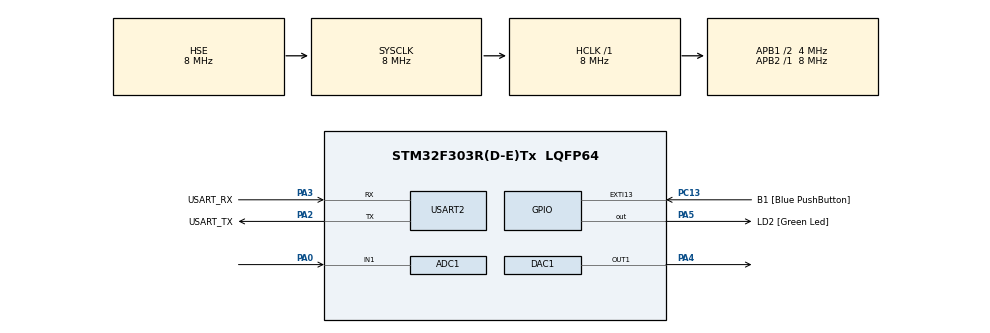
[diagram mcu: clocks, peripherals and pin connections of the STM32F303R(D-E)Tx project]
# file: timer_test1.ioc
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ADC1.Channel-0\#ChannelRegularConversion=ADC_CHANNEL_1
ADC1.NbrOfConversionFlag=1
ADC1.Offset-0\#ChannelRegularConversion=0
ADC1.OffsetNumber-0\#ChannelRegularConversion=ADC_OFFSET_NONE
ADC1.Rank-0\#ChannelRegularConversion=1
ADC1.SamplingTime-0\#ChannelRegularConversion=ADC_SAMPLETIME_1CYCLE_5
ADC1.master=1
Mcu.Family=STM32F3
Mcu.Name=STM32F303R(D-E)Tx
Mcu.Package=LQFP64
NVIC.PriorityGroup=NVIC_PRIORITYGROUP_0
NVIC.TIM3_IRQn=true\:0\:0\:false\:false\:true\:true\:true
PA0.Mode=IN1-Single-Ended
PA0.Signal=ADC1_IN1
PA13.GPIO_Label=TMS
PA13.Mode=Serial_Wire
PA13.Signal=SYS_JTMS-SWDIO
PA14.GPIO_Label=TCK
PA14.Mode=Serial_Wire
PA14.Signal=SYS_JTCK-SWCLK
PA2.GPIO_Label=USART_TX
PA2.GPIO_Mode=GPIO_MODE_AF_PP
PA2.GPIO_PuPd=GPIO_NOPULL
PA2.GPIO_Speed=GPIO_SPEED_FREQ_LOW
PA2.Mode=Asynchronous
PA2.Signal=USART2_TX
PA3.GPIO_Label=USART_RX
PA3.GPIO_Mode=GPIO_MODE_AF_PP
PA3.GPIO_PuPd=GPIO_NOPULL
PA3.GPIO_Speed=GPIO_SPEED_FREQ_LOW
PA3.Mode=Asynchronous
PA3.Signal=USART2_RX
PA4.Signal=COMP_DAC11_group
PA5.GPIO_Label=LD2 [Green Led]
PA5.GPIO_Mode=GPIO_MODE_OUTPUT_PP
PA5.GPIO_PuPd=GPIO_NOPULL
PA5.GPIO_Speed=GPIO_SPEED_FREQ_LOW
PA5.Signal=GPIO_Output
PB3.GPIO_Label=SWO
PB3.Signal=SYS_JTDO-TRACESWO
PC13.GPIO_Label=B1 [Blue PushButton]
PC13.GPIO_ModeDefaultEXTI=GPIO_MODE_IT_FALLING
PC13.Signal=GPXTI13
PC14-OSC32_IN.Signal=RCC_OSC32_IN
PC15-OSC32_OUT.Signal=RCC_OSC32_OUT
PF0-OSC_IN.Mode=HSE-External-Oscillator
PF0-OSC_IN.Signal=RCC_OSC_IN
PF1-OSC_OUT.Mode=HSE-External-Oscillator
PF1-OSC_OUT.Signal=RCC_OSC_OUT
ProjectManager.HeapSize=0x200
ProjectManager.StackSize=0x400
ProjectManager.TargetToolchain=MDK-ARM V5
RCC.AHBFreq_Value=8000000
RCC.APB1CLKDivider=RCC_HCLK_DIV2
RCC.APB1Freq_Value=4000000
RCC.APB1TimFreq_Value=8000000
RCC.APB2Freq_Value=8000000
RCC.APB2TimFreq_Value=8000000
RCC.CortexFreq_Value=8000000
RCC.HCLKFreq_Value=8000000
RCC.HSE_VALUE=8000000
RCC.HSI_VALUE=8000000
RCC.LSE_VALUE=32768
RCC.PLLM=8
RCC.PLLMUL=RCC_PLL_MUL9
RCC.PLLN=336
RCC.PLLP=RCC_PLLP_DIV4
RCC.PLLQ=7
RCC.PLLSourceVirtual=RCC_PLLSOURCE_HSE
RCC.RCC_PLLsource_Clock_Source_FROM_HSE=RCC_HSE_PREDIV_DIV2
RCC.SYSCLKFreq_VALUE=8000000
RCC.SYSCLKSourceVirtual=RCC_SYSCLKSOURCE_HSE
RCC.USBFreq_Value=72000000
SH.COMP_DAC11_group.0=DAC1_OUT1,DAC_OUT1
TIM3.Period=19
TIM3.Prescaler=79
USART2.VirtualMode-Asynchronous=VM_ASYNC
VP_TIM3_VS_ClockSourceINT.Mode=Internal
board=NUCLEO-F303RE

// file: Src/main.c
/* USER CODE BEGIN Header */
/**
  ******************************************************************************
  * @file           : main.c
  * @brief          : Main program body
  ******************************************************************************
  * @attention
  *
  * <h2><center>&copy; Copyright (c) 2019 STMicroelectronics.
  * All rights reserved.</center></h2>
  *
  * This software component is licensed by ST under BSD 3-Clause license,
  * the "License"; You may not use this file except in compliance with the
  * License. You may obtain a copy of the License at:
  *                        opensource.org/licenses/BSD-3-Clause
  *
  ******************************************************************************
  */
/* USER CODE END Header */

#include "main.h"

ADC_HandleTypeDef hadc1;

DAC_HandleTypeDef hdac1;

TIM_HandleTypeDef htim3;

UART_HandleTypeDef huart2;

uint32_t dacInput,up;
float dac_value_variable=2;
float dac_output_variable;

void SystemClock_Config(void);
static void MX_GPIO_Init(void);
static void MX_ADC1_Init(void);
static void MX_DAC1_Init(void);
static void MX_TIM3_Init(void);
static void MX_USART2_UART_Init(void);

/* USER CODE BEGIN 0 */
void HAL_TIM_PeriodElapsedCallback(TIM_HandleTypeDef*htim)
{

	if(htim->Instance==TIM3)
	{
		if(up==1)
		{
			dacInput=dacInput+256;
			if (dacInput==3840)
			{up=1;}
		}
		else
		{dacInput=dacInput-256;
			if (dacInput==0)
			{up =1;}
		}
	}

	HAL_DAC_Start(&hdac1, DAC_CHANNEL_1);
	HAL_DAC_SetValue(&hdac1,DAC_CHANNEL_1,DAC_ALIGN_8B_R,dac_value_variable);
	dac_output_variable=(3300*dac_value_variable)/4096;
}
/* USER CODE END 0 */

int main(void)
{

  /* MCU Configuration--------------------------------------------------------*/

  /* Reset of all peripherals, Initializes the Flash interface and the Systick. */
  HAL_Init();

  /* Configure the system clock */
  SystemClock_Config();

  /* Initialize all configured peripherals */
  MX_GPIO_Init();
  MX_ADC1_Init();
  MX_DAC1_Init();
  MX_TIM3_Init();
  MX_USART2_UART_Init();
  /* USER CODE BEGIN 2 */
	HAL_TIM_Base_Start_IT(&htim3);
  /* USER CODE END 2 */

  /* Infinite loop */
  while (1)
  {

  }
}

void SystemClock_Config(void)
{
  RCC_OscInitTypeDef RCC_OscInitStruct = {0};
  RCC_ClkInitTypeDef RCC_ClkInitStruct = {0};
  RCC_PeriphCLKInitTypeDef PeriphClkInit = {0};

  /** Initializes the CPU, AHB and APB busses clocks
  */
  RCC_OscInitStruct.OscillatorType = RCC_OSCILLATORTYPE_HSE;
  RCC_OscInitStruct.HSEState = RCC_HSE_ON;
  RCC_OscInitStruct.HSIState = RCC_HSI_ON;
  RCC_OscInitStruct.PLL.PLLState = RCC_PLL_ON;
  RCC_OscInitStruct.PLL.PLLSource = RCC_PLLSOURCE_HSE;
  RCC_OscInitStruct.PLL.PLLMUL = RCC_PLL_MUL9;
  RCC_OscInitStruct.PLL.PREDIV = RCC_PREDIV_DIV1;
  if (HAL_RCC_OscConfig(&RCC_OscInitStruct) != HAL_OK)
  {
    Error_Handler();
  }
  /** Initializes the CPU, AHB and APB busses clocks
  */
  RCC_ClkInitStruct.ClockType = RCC_CLOCKTYPE_HCLK|RCC_CLOCKTYPE_SYSCLK
                              |RCC_CLOCKTYPE_PCLK1|RCC_CLOCKTYPE_PCLK2;
  RCC_ClkInitStruct.SYSCLKSource = RCC_SYSCLKSOURCE_HSE;
  RCC_ClkInitStruct.AHBCLKDivider = RCC_SYSCLK_DIV1;
  RCC_ClkInitStruct.APB1CLKDivider = RCC_HCLK_DIV2;
  RCC_ClkInitStruct.APB2CLKDivider = RCC_HCLK_DIV1;

  if (HAL_RCC_ClockConfig(&RCC_ClkInitStruct, FLASH_LATENCY_0) != HAL_OK)
  {
    Error_Handler();
  }
  PeriphClkInit.PeriphClockSelection = RCC_PERIPHCLK_USART2|RCC_PERIPHCLK_ADC12
                              |RCC_PERIPHCLK_TIM34;
  PeriphClkInit.Usart2ClockSelection = RCC_USART2CLKSOURCE_PCLK1;
  PeriphClkInit.Adc12ClockSelection = RCC_ADC12PLLCLK_DIV1;
  PeriphClkInit.Tim34ClockSelection = RCC_TIM34CLK_HCLK;
  if (HAL_RCCEx_PeriphCLKConfig(&PeriphClkInit) != HAL_OK)
  {
    Error_Handler();
  }
}

static void MX_ADC1_Init(void)
{

  ADC_MultiModeTypeDef multimode = {0};
  ADC_ChannelConfTypeDef sConfig = {0};

  /** Common config
  */
  hadc1.Instance = ADC1;
  hadc1.Init.ClockPrescaler = ADC_CLOCK_ASYNC_DIV1;
  hadc1.Init.Resolution = ADC_RESOLUTION_12B;
  hadc1.Init.ScanConvMode = ADC_SCAN_DISABLE;
  hadc1.Init.ContinuousConvMode = DISABLE;
  hadc1.Init.DiscontinuousConvMode = DISABLE;
  hadc1.Init.ExternalTrigConvEdge = ADC_EXTERNALTRIGCONVEDGE_NONE;
  hadc1.Init.ExternalTrigConv = ADC_SOFTWARE_START;
  hadc1.Init.DataAlign = ADC_DATAALIGN_RIGHT;
  hadc1.Init.NbrOfConversion = 1;
  hadc1.Init.DMAContinuousRequests = DISABLE;
  hadc1.Init.EOCSelection = ADC_EOC_SINGLE_CONV;
  hadc1.Init.LowPowerAutoWait = DISABLE;
  hadc1.Init.Overrun = ADC_OVR_DATA_OVERWRITTEN;
  if (HAL_ADC_Init(&hadc1) != HAL_OK)
  {
    Error_Handler();
  }
  /** Configure the ADC multi-mode
  */
  multimode.Mode = ADC_MODE_INDEPENDENT;
  if (HAL_ADCEx_MultiModeConfigChannel(&hadc1, &multimode) != HAL_OK)
  {
    Error_Handler();
  }
  /** Configure Regular Channel
  */
  sConfig.Channel = ADC_CHANNEL_1;
  sConfig.Rank = ADC_REGULAR_RANK_1;
  sConfig.SingleDiff = ADC_SINGLE_ENDED;
  sConfig.SamplingTime = ADC_SAMPLETIME_1CYCLE_5;
  sConfig.OffsetNumber = ADC_OFFSET_NONE;
  sConfig.Offset = 0;
  if (HAL_ADC_ConfigChannel(&hadc1, &sConfig) != HAL_OK)
  {
    Error_Handler();
  }

}

static void MX_DAC1_Init(void)
{

  DAC_ChannelConfTypeDef sConfig = {0};

  /** DAC Initialization
  */
  hdac1.Instance = DAC1;
  if (HAL_DAC_Init(&hdac1) != HAL_OK)
  {
    Error_Handler();
  }
  /** DAC channel OUT1 config
  */
  sConfig.DAC_Trigger = DAC_TRIGGER_NONE;
  sConfig.DAC_OutputBuffer = DAC_OUTPUTBUFFER_ENABLE;
  if (HAL_DAC_ConfigChannel(&hdac1, &sConfig, DAC_CHANNEL_1) != HAL_OK)
  {
    Error_Handler();
  }

}

static void MX_TIM3_Init(void)
{

  TIM_ClockConfigTypeDef sClockSourceConfig = {0};
  TIM_MasterConfigTypeDef sMasterConfig = {0};

  htim3.Instance = TIM3;
  htim3.Init.Prescaler = 79;
  htim3.Init.CounterMode = TIM_COUNTERMODE_UP;
  htim3.Init.Period = 19;
  htim3.Init.ClockDivision = TIM_CLOCKDIVISION_DIV1;
  htim3.Init.AutoReloadPreload = TIM_AUTORELOAD_PRELOAD_DISABLE;
  if (HAL_TIM_Base_Init(&htim3) != HAL_OK)
  {
    Error_Handler();
  }
  sClockSourceConfig.ClockSource = TIM_CLOCKSOURCE_INTERNAL;
  if (HAL_TIM_ConfigClockSource(&htim3, &sClockSourceConfig) != HAL_OK)
  {
    Error_Handler();
  }
  sMasterConfig.MasterOutputTrigger = TIM_TRGO_RESET;
  sMasterConfig.MasterSlaveMode = TIM_MASTERSLAVEMODE_DISABLE;
  if (HAL_TIMEx_MasterConfigSynchronization(&htim3, &sMasterConfig) != HAL_OK)
  {
    Error_Handler();
  }

}

static void MX_USART2_UART_Init(void)
{

  huart2.Instance = USART2;
  huart2.Init.BaudRate = 38400;
  huart2.Init.WordLength = UART_WORDLENGTH_8B;
  huart2.Init.StopBits = UART_STOPBITS_1;
  huart2.Init.Parity = UART_PARITY_NONE;
  huart2.Init.Mode = UART_MODE_TX_RX;
  huart2.Init.HwFlowCtl = UART_HWCONTROL_NONE;
  huart2.Init.OverSampling = UART_OVERSAMPLING_16;
  huart2.Init.OneBitSampling = UART_ONE_BIT_SAMPLE_DISABLE;
  huart2.AdvancedInit.AdvFeatureInit = UART_ADVFEATURE_NO_INIT;
  if (HAL_UART_Init(&huart2) != HAL_OK)
  {
    Error_Handler();
  }

}

static void MX_GPIO_Init(void)
{
  GPIO_InitTypeDef GPIO_InitStruct = {0};

  /* GPIO Ports Clock Enable */
  __HAL_RCC_GPIOC_CLK_ENABLE();
  __HAL_RCC_GPIOF_CLK_ENABLE();
  __HAL_RCC_GPIOA_CLK_ENABLE();
  __HAL_RCC_GPIOB_CLK_ENABLE();

  /*Configure GPIO pin Output Level */
  HAL_GPIO_WritePin(LD2_GPIO_Port, LD2_Pin, GPIO_PIN_RESET);

  /*Configure GPIO pin : B1_Pin */
  GPIO_InitStruct.Pin = B1_Pin;
  GPIO_InitStruct.Mode = GPIO_MODE_IT_FALLING;
  GPIO_InitStruct.Pull = GPIO_NOPULL;
  HAL_GPIO_Init(B1_GPIO_Port, &GPIO_InitStruct);

  /*Configure GPIO pin : LD2_Pin */
  GPIO_InitStruct.Pin = LD2_Pin;
  GPIO_InitStruct.Mode = GPIO_MODE_OUTPUT_PP;
  GPIO_InitStruct.Pull = GPIO_NOPULL;
  GPIO_InitStruct.Speed = GPIO_SPEED_FREQ_LOW;
  HAL_GPIO_Init(LD2_GPIO_Port, &GPIO_InitStruct);

}

void Error_Handler(void)
{
}

/************************ (C) COPYRIGHT STMicroelectronics *****END OF FILE****/
